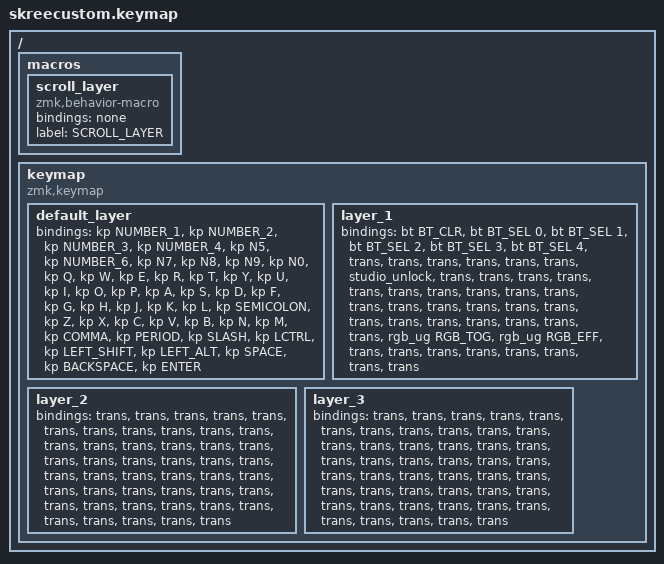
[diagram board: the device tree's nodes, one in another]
/*
 * Copyright (c) 2020 The ZMK Contributors
 *
 * SPDX-License-Identifier: MIT
 */
//#include <behaviors/mouse_keys.dtsi>

#include <behaviors.dtsi>
#include <dt-bindings/zmk/bt.h>
#include <dt-bindings/zmk/keys.h>
#include <dt-bindings/zmk/rgb.h>

/ {
    macros {
        scroll_layer: scroll_layer {
            compatible = "zmk,behavior-macro";
            #binding-cells = <0>;
            bindings = <&none>;
            label = "SCROLL_LAYER";
        };
    };

    keymap {
        compatible = "zmk,keymap";

        default_layer {
            bindings = <
&kp NUMBER_1  &kp NUMBER_2  &kp NUMBER_3  &kp NUMBER_4  &kp N5  &kp NUMBER_6  &kp N7  &kp N8  &kp N9  &kp N0  &kp Q  &kp W  &kp E  &kp R  &kp T  &kp Y  &kp U  &kp I  &kp O  &kp P  &kp A  &kp S  &kp D  &kp F  &kp G  &kp H  &kp J  &kp K  &kp L  &kp SEMICOLON  &kp Z  &kp X  &kp C  &kp V  &kp B  &kp N  &kp M  &kp COMMA  &kp PERIOD  &kp SLASH  &kp LCTRL  &kp LEFT_SHIFT  &kp LEFT_ALT  &kp SPACE  &kp BACKSPACE  &kp ENTER
            >;
        };

        layer_1 {
            bindings = <
&bt BT_CLR  &bt BT_SEL 0  &bt BT_SEL 1  &bt BT_SEL 2  &bt BT_SEL 3  &bt BT_SEL 4  &trans  &trans  &trans  &trans  &trans  &trans  &studio_unlock  &trans  &trans  &trans  &trans  &trans  &trans  &trans  &trans  &trans  &trans  &trans  &trans  &trans  &trans  &trans  &trans  &trans  &trans  &trans  &trans  &trans  &trans  &trans  &rgb_ug RGB_TOG  &rgb_ug RGB_EFF  &trans  &trans  &trans  &trans  &trans  &trans  &trans  &trans
            >;
        };

        layer_2 {
            bindings = <
&trans  &trans  &trans  &trans  &trans  &trans  &trans  &trans  &trans  &trans  &trans  &trans  &trans  &trans  &trans  &trans  &trans  &trans  &trans  &trans  &trans  &trans  &trans  &trans  &trans  &trans  &trans  &trans  &trans  &trans  &trans  &trans  &trans  &trans  &trans  &trans  &trans  &trans  &trans  &trans  &trans  &trans  &trans  &trans  &trans  &trans
            >;
        };

        layer_3 {
            bindings = <
&trans  &trans  &trans  &trans  &trans  &trans  &trans  &trans  &trans  &trans  &trans  &trans  &trans  &trans  &trans  &trans  &trans  &trans  &trans  &trans  &trans  &trans  &trans  &trans  &trans  &trans  &trans  &trans  &trans  &trans  &trans  &trans  &trans  &trans  &trans  &trans  &trans  &trans  &trans  &trans  &trans  &trans  &trans  &trans  &trans  &trans
            >;
        };
    };
};
